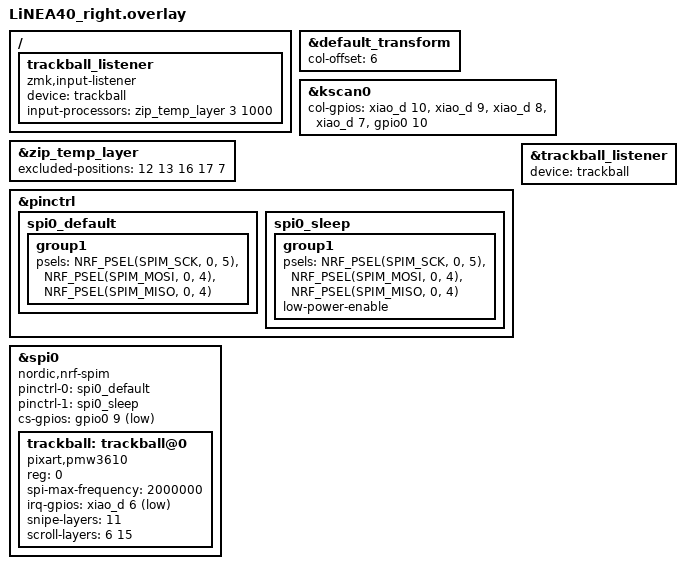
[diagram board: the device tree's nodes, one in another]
#include <input/processors.dtsi>
#include "LiNEA40.dtsi"
&default_transform {
    col-offset = <6>;
};

&kscan0 {
    col-gpios
        = <&xiao_d 10 GPIO_ACTIVE_HIGH> //col0-D10
        , <&xiao_d 9 GPIO_ACTIVE_HIGH>  //col1-D9
        , <&xiao_d 8 GPIO_ACTIVE_HIGH>  //col2-D8
        , <&xiao_d 7 GPIO_ACTIVE_HIGH>  //col3-D7
        , <&gpio0 10 GPIO_ACTIVE_HIGH>  //col4-NFC2
        ;
};

&zip_temp_layer {
    excluded-positions = <
        12 // D
        13 // F
        16 // J
        17 // K
        7 //  I
    >;
};


/ {
    trackball_listener {
        compatible = "zmk,input-listener";
        device = <&trackball>;

        /*
         * トラックボール入力に一時レイヤー処理を追加
         *
         * zip_temp_layer:
         *   指定した入力が来たときに、一時的にレイヤーを有効化する
         *
         * 引数:
         *   2     : 一時的に有効化するレイヤー番号
         *   10000 : タイムアウト（ミリ秒）
         *
         * → トラックボール操作中のみ Layer3 を有効にする用途
         */
        input-processors = <&zip_temp_layer 3 1000>;
    };
};


&pinctrl {
    spi0_default: spi0_default {
        group1 {
            psels = <NRF_PSEL(SPIM_SCK, 0, 5)>   // SCLK-D5
                  , <NRF_PSEL(SPIM_MOSI, 0, 4)>  // SDIO-D4
                  , <NRF_PSEL(SPIM_MISO, 0, 4)>  // SDIO-D4
                  ;
        };
    };

    spi0_sleep: spi0_sleep {
        group1 {
            psels = <NRF_PSEL(SPIM_SCK, 0, 5)>   // SCLK-D5
                  , <NRF_PSEL(SPIM_MOSI, 0, 4)>  // SDIO-D4
                  , <NRF_PSEL(SPIM_MISO, 0, 4)>  // SDIO-D4
                  ;
            low-power-enable;
        };
    };
};

&spi0 {
    status = "okay";
    compatible = "nordic,nrf-spim";
    pinctrl-0 = <&spi0_default>;
    pinctrl-1 = <&spi0_sleep>;
    pinctrl-names = "default", "sleep";
    cs-gpios = <&gpio0 9 GPIO_ACTIVE_LOW>; //NCS-NFC1

    trackball: trackball@0 {
        status = "okay";
        compatible = "pixart,pmw3610";
        reg = <0>;
        spi-max-frequency = <2000000>;
        irq-gpios = <&xiao_d 6 (GPIO_ACTIVE_LOW | GPIO_PULL_UP)>; //MOT-D6
        //automouse-layer = <1>;
        // snipe精密モード: レイヤー11(Snipe)が有効な間 SNIPE_CPI=450/DIVIDOR=2 (1/4速)。
        // 発動キーはLineaStudioから &mo 11 (Momentary/Snipe) をランタイム割当できる。
        // 注意: レイヤーindex固定のため、StudioでSnipe層を並べ替えるとズレる
        snipe-layers = <11>;
        // 6=Symbol(スペース保持)。15=JIS Sym はJISモード時のスペース保持で入る同役割層なので
        // 同じくトラックボールをスクロール化する（indexはビルド時固定・並べ替え注意は snipe と同じ）
        scroll-layers = <6 15>;
        //scroll-layers = <4 5 6>;
    };
};

&trackball_listener {
    status = "okay";
    device = <&trackball>;
};
